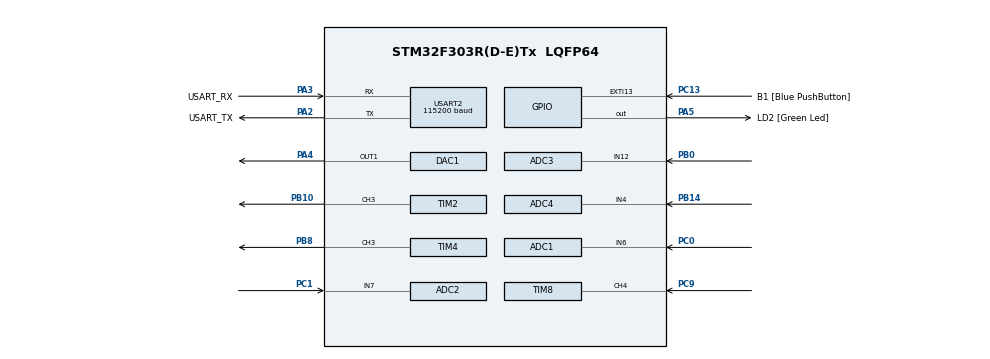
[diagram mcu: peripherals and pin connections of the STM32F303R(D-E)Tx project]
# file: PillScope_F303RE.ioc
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ADC1.AWD1HighThreshold=4095
ADC1.AWD1ITMode=ENABLE
ADC1.Channel-1\#ChannelRegularConversion=ADC_CHANNEL_VREFINT
ADC1.Channel-2\#ChannelRegularConversion=ADC_CHANNEL_6
ADC1.ClockPrescaler=ADC_CLOCK_SYNC_PCLK_DIV2
ADC1.DMAContinuousRequests=ENABLE
ADC1.EnableAnalogWatchDog1=true
ADC1.EnableInjectedConversion=DISABLE
ADC1.ExternalTrigConv=ADC_EXTERNALTRIGCONV_T3_TRGO
ADC1.NbrOfConversion=2
ADC1.NbrOfConversionFlag=1
ADC1.Offset-1\#ChannelRegularConversion=0
ADC1.Offset-2\#ChannelRegularConversion=0
ADC1.OffsetNumber-1\#ChannelRegularConversion=ADC_OFFSET_NONE
ADC1.OffsetNumber-2\#ChannelRegularConversion=ADC_OFFSET_NONE
ADC1.Rank-1\#ChannelRegularConversion=1
ADC1.Rank-2\#ChannelRegularConversion=2
ADC1.SamplingTime-1\#ChannelRegularConversion=ADC_SAMPLETIME_1CYCLE_5
ADC1.SamplingTime-2\#ChannelRegularConversion=ADC_SAMPLETIME_1CYCLE_5
ADC1.WatchdogChannel=ADC_CHANNEL_VREFINT
ADC1.master=1
ADC2.AWD1HighThreshold=4095
ADC2.AWD1ITMode=ENABLE
ADC2.Channel-1\#ChannelRegularConversion=ADC_CHANNEL_7
ADC2.ClockPrescaler=ADC_CLOCK_SYNC_PCLK_DIV2
ADC2.DMAContinuousRequests=ENABLE
ADC2.EnableAnalogWatchDog1=true
ADC2.ExternalTrigConv=ADC_EXTERNALTRIGCONV_T3_TRGO
ADC2.NbrOfConversion=1
ADC2.NbrOfConversionFlag=1
ADC2.Offset-1\#ChannelRegularConversion=0
ADC2.OffsetNumber-1\#ChannelRegularConversion=ADC_OFFSET_NONE
ADC2.Rank-1\#ChannelRegularConversion=1
ADC2.SamplingTime-1\#ChannelRegularConversion=ADC_SAMPLETIME_1CYCLE_5
ADC2.WatchdogChannel=ADC_CHANNEL_7
ADC3.AWD1HighThreshold=4095
ADC3.AWD1ITMode=ENABLE
ADC3.Channel-0\#ChannelRegularConversion=ADC_CHANNEL_12
ADC3.ClockPrescaler=ADC_CLOCK_SYNC_PCLK_DIV2
ADC3.DMAContinuousRequests=ENABLE
ADC3.EnableAnalogWatchDog1=true
ADC3.ExternalTrigConv=ADC_EXTERNALTRIGCONV_T3_TRGO
ADC3.NbrOfConversionFlag=1
ADC3.Offset-0\#ChannelRegularConversion=0
ADC3.OffsetNumber-0\#ChannelRegularConversion=ADC_OFFSET_NONE
ADC3.Rank-0\#ChannelRegularConversion=1
ADC3.SamplingTime-0\#ChannelRegularConversion=ADC_SAMPLETIME_1CYCLE_5
ADC3.WatchdogChannel=ADC_CHANNEL_12
ADC3.master=1
ADC4.AWD1HighThreshold=4095
ADC4.AWD1ITMode=ENABLE
ADC4.Channel-0\#ChannelRegularConversion=ADC_CHANNEL_4
ADC4.ClockPrescaler=ADC_CLOCK_SYNC_PCLK_DIV2
ADC4.DMAContinuousRequests=ENABLE
ADC4.EnableAnalogWatchDog1=true
ADC4.ExternalTrigConv=ADC_EXTERNALTRIGCONV_T3_TRGO
ADC4.NbrOfConversionFlag=1
ADC4.Offset-0\#ChannelRegularConversion=0
ADC4.OffsetNumber-0\#ChannelRegularConversion=ADC_OFFSET_NONE
ADC4.Rank-0\#ChannelRegularConversion=1
ADC4.SamplingTime-0\#ChannelRegularConversion=ADC_SAMPLETIME_1CYCLE_5
ADC4.SamplingTimeOPAMP-0\#ChannelRegularConversion=ADC_SAMPLETIME_61CYCLES_5
ADC4.WatchdogChannel=ADC_CHANNEL_4
DAC1.DAC_Trigger=DAC_TRIGGER_T6_TRGO
Dma.ADC1.0.Direction=DMA_PERIPH_TO_MEMORY
Dma.ADC1.0.Instance=DMA1_Channel1
Dma.ADC1.0.MemDataAlignment=DMA_MDATAALIGN_HALFWORD
Dma.ADC1.0.MemInc=DMA_MINC_ENABLE
Dma.ADC1.0.Mode=DMA_CIRCULAR
Dma.ADC1.0.PeriphDataAlignment=DMA_PDATAALIGN_HALFWORD
Dma.ADC1.0.PeriphInc=DMA_PINC_DISABLE
Dma.ADC1.0.Priority=DMA_PRIORITY_VERY_HIGH
Dma.ADC2.1.Direction=DMA_PERIPH_TO_MEMORY
Dma.ADC2.1.Instance=DMA2_Channel3
Dma.ADC2.1.MemDataAlignment=DMA_MDATAALIGN_HALFWORD
Dma.ADC2.1.MemInc=DMA_MINC_ENABLE
Dma.ADC2.1.Mode=DMA_CIRCULAR
Dma.ADC2.1.PeriphDataAlignment=DMA_PDATAALIGN_HALFWORD
Dma.ADC2.1.PeriphInc=DMA_PINC_DISABLE
Dma.ADC2.1.Priority=DMA_PRIORITY_VERY_HIGH
Dma.ADC3.2.Direction=DMA_PERIPH_TO_MEMORY
Dma.ADC3.2.Instance=DMA2_Channel5
Dma.ADC3.2.MemDataAlignment=DMA_MDATAALIGN_HALFWORD
Dma.ADC3.2.MemInc=DMA_MINC_ENABLE
Dma.ADC3.2.Mode=DMA_NORMAL
Dma.ADC3.2.PeriphDataAlignment=DMA_PDATAALIGN_HALFWORD
Dma.ADC3.2.PeriphInc=DMA_PINC_DISABLE
Dma.ADC3.2.Priority=DMA_PRIORITY_VERY_HIGH
Dma.ADC4.3.Direction=DMA_PERIPH_TO_MEMORY
Dma.ADC4.3.Instance=DMA2_Channel4
Dma.ADC4.3.MemDataAlignment=DMA_MDATAALIGN_HALFWORD
Dma.ADC4.3.MemInc=DMA_MINC_ENABLE
Dma.ADC4.3.Mode=DMA_CIRCULAR
Dma.ADC4.3.PeriphDataAlignment=DMA_PDATAALIGN_HALFWORD
Dma.ADC4.3.PeriphInc=DMA_PINC_DISABLE
Dma.ADC4.3.Priority=DMA_PRIORITY_VERY_HIGH
Dma.DAC1_CH1.5.Direction=DMA_MEMORY_TO_PERIPH
Dma.DAC1_CH1.5.Instance=DMA1_Channel3
Dma.DAC1_CH1.5.MemDataAlignment=DMA_MDATAALIGN_HALFWORD
Dma.DAC1_CH1.5.MemInc=DMA_MINC_ENABLE
Dma.DAC1_CH1.5.Mode=DMA_CIRCULAR
Dma.DAC1_CH1.5.PeriphDataAlignment=DMA_PDATAALIGN_HALFWORD
Dma.DAC1_CH1.5.PeriphInc=DMA_PINC_DISABLE
Dma.DAC1_CH1.5.Priority=DMA_PRIORITY_HIGH
Dma.Request0=ADC1
Dma.Request1=ADC2
Dma.Request2=ADC3
Dma.Request3=ADC4
Dma.Request4=TIM3_CH1/TRIG
Dma.Request5=DAC1_CH1
Dma.Request6=TIM8_CH4/TRIG/COM
Dma.TIM3_CH1/TRIG.4.Direction=DMA_PERIPH_TO_MEMORY
Dma.TIM3_CH1/TRIG.4.Instance=DMA1_Channel6
Dma.TIM3_CH1/TRIG.4.MemDataAlignment=DMA_MDATAALIGN_HALFWORD
Dma.TIM3_CH1/TRIG.4.MemInc=DMA_MINC_ENABLE
Dma.TIM3_CH1/TRIG.4.Mode=DMA_CIRCULAR
Dma.TIM3_CH1/TRIG.4.PeriphDataAlignment=DMA_PDATAALIGN_HALFWORD
Dma.TIM3_CH1/TRIG.4.PeriphInc=DMA_PINC_DISABLE
Dma.TIM3_CH1/TRIG.4.Priority=DMA_PRIORITY_VERY_HIGH
Dma.TIM8_CH4/TRIG/COM.6.Direction=DMA_PERIPH_TO_MEMORY
Dma.TIM8_CH4/TRIG/COM.6.Instance=DMA2_Channel2
Dma.TIM8_CH4/TRIG/COM.6.MemDataAlignment=DMA_MDATAALIGN_HALFWORD
Dma.TIM8_CH4/TRIG/COM.6.MemInc=DMA_MINC_ENABLE
Dma.TIM8_CH4/TRIG/COM.6.Mode=DMA_NORMAL
Dma.TIM8_CH4/TRIG/COM.6.PeriphDataAlignment=DMA_PDATAALIGN_HALFWORD
Dma.TIM8_CH4/TRIG/COM.6.PeriphInc=DMA_PINC_DISABLE
Dma.TIM8_CH4/TRIG/COM.6.Priority=DMA_PRIORITY_HIGH
Mcu.Family=STM32F3
Mcu.Name=STM32F303R(D-E)Tx
Mcu.Package=LQFP64
NVIC.PriorityGroup=NVIC_PRIORITYGROUP_4
PA13.GPIO_Label=TMS
PA13.Mode=Serial_Wire
PA13.Signal=SYS_JTMS-SWDIO
PA14.GPIO_Label=TCK
PA14.Mode=Serial_Wire
PA14.Signal=SYS_JTCK-SWCLK
PA2.GPIO_Label=USART_TX
PA2.GPIO_Mode=GPIO_MODE_AF_PP
PA2.GPIO_PuPd=GPIO_NOPULL
PA2.GPIO_Speed=GPIO_SPEED_FREQ_LOW
PA2.Mode=Asynchronous
PA2.Signal=USART2_TX
PA3.GPIO_Label=USART_RX
PA3.GPIO_Mode=GPIO_MODE_AF_PP
PA3.GPIO_PuPd=GPIO_NOPULL
PA3.GPIO_Speed=GPIO_SPEED_FREQ_LOW
PA3.Mode=Asynchronous
PA3.Signal=USART2_RX
PA4.Signal=COMP_DAC11_group
PA5.GPIO_Label=LD2 [Green Led]
PA5.GPIO_Mode=GPIO_MODE_OUTPUT_PP
PA5.GPIO_PuPd=GPIO_NOPULL
PA5.GPIO_Speed=GPIO_SPEED_FREQ_LOW
PA5.Signal=GPIO_Output
PB0.Mode=IN12-Single-Ended
PB0.Signal=ADC3_IN12
PB10.Signal=S_TIM2_CH3
PB14.Mode=IN4-Single-Ended
PB14.Signal=ADC4_IN4
PB3.GPIO_Label=SWO
PB3.Signal=SYS_JTDO-TRACESWO
PB8.Signal=S_TIM4_CH3
PC0.Signal=ADCx_IN6
PC1.Signal=ADCx_IN7
PC13.GPIO_Label=B1 [Blue PushButton]
PC13.GPIO_ModeDefaultEXTI=GPIO_MODE_IT_FALLING
PC13.Signal=GPXTI13
PC14-OSC32_IN.Mode=LSE-External-Oscillator
PC14-OSC32_IN.Signal=RCC_OSC32_IN
PC15-OSC32_OUT.Mode=LSE-External-Oscillator
PC15-OSC32_OUT.Signal=RCC_OSC32_OUT
PC9.Signal=S_TIM8_CH4
PF0-OSC_IN.Mode=HSE-External-Clock-Source
PF0-OSC_IN.Signal=RCC_OSC_IN
PF1-OSC_OUT.Signal=RCC_OSC_OUT
ProjectManager.HeapSize=0x200
ProjectManager.StackSize=0x400
ProjectManager.TargetToolchain=STM32CubeIDE
RCC.AHBFreq_Value=72000000
RCC.APB1CLKDivider=RCC_HCLK_DIV2
RCC.APB1Freq_Value=36000000
RCC.APB1TimFreq_Value=72000000
RCC.APB2Freq_Value=72000000
RCC.APB2TimFreq_Value=72000000
RCC.CortexFreq_Value=72000000
RCC.HCLKFreq_Value=72000000
RCC.HSE_VALUE=8000000
RCC.HSI_VALUE=8000000
RCC.PLLM=8
RCC.PLLMUL=RCC_PLL_MUL9
RCC.PLLN=336
RCC.PLLP=RCC_PLLP_DIV4
RCC.PLLQ=7
RCC.RCC_PLLsource_Clock_Source_FROM_HSE=RCC_HSE_PREDIV_DIV2
RCC.SYSCLKFreq_VALUE=72000000
RCC.SYSCLKSourceVirtual=RCC_SYSCLKSOURCE_PLLCLK
RCC.USBFreq_Value=72000000
SH.ADCx_IN6.0=ADC1_IN6,IN6-Single-Ended
SH.ADCx_IN7.0=ADC2_IN7,IN7-Single-Ended
SH.COMP_DAC11_group.0=DAC1_OUT1,DAC_OUT1
SH.S_TIM2_CH3.0=TIM2_CH3,PWM Generation3 CH3
SH.S_TIM4_CH3.0=TIM4_CH3,PWM Generation3 CH3
SH.S_TIM8_CH4.0=TIM8_CH4,Input_Capture4_from_TI4
TIM2.Channel-PWM\ Generation3\ CH3=TIM_CHANNEL_3
TIM2.Period=1000
TIM2.TIM_MasterOutputTrigger=TIM_TRGO_ENABLE
TIM2.TIM_MasterSlaveMode=TIM_MASTERSLAVEMODE_ENABLE
TIM3.AutoReloadPreload=TIM_AUTORELOAD_PRELOAD_ENABLE
TIM3.Channel-Output\ Compare1\ No\ Output=TIM_CHANNEL_1
TIM3.Period=72
TIM3.Prescaler=1000
TIM3.TIM_MasterOutputTrigger=TIM_TRGO_UPDATE
TIM4.AutoReloadPreload=TIM_AUTORELOAD_PRELOAD_ENABLE
TIM4.Channel-PWM\ Generation3\ CH3=TIM_CHANNEL_3
TIM4.Period=73
TIM4.Prescaler=1000
TIM4.TIM_MasterOutputTrigger=TIM_TRGO_UPDATE
TIM6.TIM_MasterOutputTrigger=TIM_TRGO_UPDATE
TIM8.AutoReloadPreload=TIM_AUTORELOAD_PRELOAD_DISABLE
TIM8.Channel-Input_Capture4_from_TI4=TIM_CHANNEL_4
USART2.BaudRate=115200
USART2.VirtualMode-Asynchronous=VM_ASYNC
VP_ADC1_Vref_Input.Mode=IN-Vrefint
VP_TIM2_VS_ClockSourceINT.Mode=Internal
VP_TIM3_VS_ClockSourceINT.Mode=Internal
VP_TIM3_VS_no_output1.Mode=Output Compare1 No Output
VP_TIM4_VS_ClockSourceINT.Mode=Internal
VP_TIM4_VS_ClockSourceITR.Mode=TriggerSource_ITR1
VP_TIM4_VS_ControllerModeTrigger.Mode=Trigger Mode
VP_TIM6_VS_ClockSourceINT.Mode=Enable_Timer
board=NUCLEO-F303RE

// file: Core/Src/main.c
/* USER CODE BEGIN Header */
/**
  ******************************************************************************
  * @file           : main.c
  * @brief          : Main program body
  ******************************************************************************
  * @attention
  *
  * <h2><center>&copy; Copyright (c) 2021 STMicroelectronics.
  * All rights reserved.</center></h2>
  *
  * This software component is licensed by ST under BSD 3-Clause license,
  * the "License"; You may not use this file except in compliance with the
  * License. You may obtain a copy of the License at:
  *                        opensource.org/licenses/BSD-3-Clause
  *
  ******************************************************************************
  */
/* USER CODE END Header */
#include "main.h"

/* USER CODE BEGIN Includes */
#include "app.h"
/* USER CODE END Includes */

TIM_HandleTypeDef htim6;

void SystemClock_Config(void);
static void MX_GPIO_Init(void);
static void MX_DMA_Init(void);
static void MX_USART2_UART_Init(void);
static void MX_ADC1_Init(void);
static void MX_ADC2_Init(void);
static void MX_ADC3_Init(void);
static void MX_ADC4_Init(void);
static void MX_TIM3_Init(void);
static void MX_TIM2_Init(void);
static void MX_TIM4_Init(void);
static void MX_DAC1_Init(void);
static void MX_TIM8_Init(void);
static void MX_TIM6_Init(void);

int main(void)
{

  /* MCU Configuration--------------------------------------------------------*/

  /* Reset of all peripherals, Initializes the Flash interface and the Systick. */
  HAL_Init();

  /* Configure the system clock */
  SystemClock_Config();

  /* Initialize all configured peripherals */
  MX_GPIO_Init();
  MX_DMA_Init();
  MX_USART2_UART_Init();
  MX_ADC1_Init();
  MX_ADC2_Init();
  MX_ADC3_Init();
  MX_ADC4_Init();
  MX_TIM3_Init();
  MX_TIM2_Init();
  MX_TIM4_Init();
  MX_DAC1_Init();
  MX_TIM8_Init();
  MX_TIM6_Init();

  /* Infinite loop */
  /* USER CODE BEGIN WHILE */
  app_main();
    /* USER CODE END WHILE */

}

void SystemClock_Config(void)
{
  LL_FLASH_SetLatency(LL_FLASH_LATENCY_2);
  while(LL_FLASH_GetLatency()!= LL_FLASH_LATENCY_2)
  {
  }
  LL_RCC_HSI_Enable();

   /* Wait till HSI is ready */
  while(LL_RCC_HSI_IsReady() != 1)
  {

  }
  LL_RCC_HSI_SetCalibTrimming(16);
  LL_RCC_PLL_ConfigDomain_SYS(LL_RCC_PLLSOURCE_HSI, LL_RCC_PLL_MUL_9, LL_RCC_PREDIV_DIV_1);
  LL_RCC_PLL_Enable();

   /* Wait till PLL is ready */
  while(LL_RCC_PLL_IsReady() != 1)
  {

  }
  LL_RCC_SetAHBPrescaler(LL_RCC_SYSCLK_DIV_1);
  LL_RCC_SetAPB1Prescaler(LL_RCC_APB1_DIV_2);
  LL_RCC_SetAPB2Prescaler(LL_RCC_APB1_DIV_1);
  LL_RCC_SetSysClkSource(LL_RCC_SYS_CLKSOURCE_PLL);

   /* Wait till System clock is ready */
  while(LL_RCC_GetSysClkSource() != LL_RCC_SYS_CLKSOURCE_STATUS_PLL)
  {

  }
  LL_SetSystemCoreClock(72000000);

   /* Update the time base */
  if (HAL_InitTick (TICK_INT_PRIORITY) != HAL_OK)
  {
    Error_Handler();
  }
  LL_RCC_SetUSARTClockSource(LL_RCC_USART2_CLKSOURCE_PCLK1);
  LL_RCC_SetTIMClockSource(LL_RCC_TIM8_CLKSOURCE_PCLK2);
  LL_RCC_SetTIMClockSource(LL_RCC_TIM2_CLKSOURCE_PCLK1);
  LL_RCC_SetTIMClockSource(LL_RCC_TIM34_CLKSOURCE_PCLK1);
}

static void MX_ADC1_Init(void)
{

  LL_ADC_InitTypeDef ADC_InitStruct = {0};
  LL_ADC_REG_InitTypeDef ADC_REG_InitStruct = {0};
  LL_ADC_CommonInitTypeDef ADC_CommonInitStruct = {0};

  LL_GPIO_InitTypeDef GPIO_InitStruct = {0};

  /* Peripheral clock enable */
  LL_AHB1_GRP1_EnableClock(LL_AHB1_GRP1_PERIPH_ADC12);

  LL_AHB1_GRP1_EnableClock(LL_AHB1_GRP1_PERIPH_GPIOC);
  /**ADC1 GPIO Configuration
  PC0   ------> ADC1_IN6
  */
  GPIO_InitStruct.Pin = LL_GPIO_PIN_0;
  GPIO_InitStruct.Mode = LL_GPIO_MODE_ANALOG;
  GPIO_InitStruct.Pull = LL_GPIO_PULL_NO;
  LL_GPIO_Init(GPIOC, &GPIO_InitStruct);

  /* ADC1 DMA Init */

  /* ADC1 Init */
  LL_DMA_SetDataTransferDirection(DMA1, LL_DMA_CHANNEL_1, LL_DMA_DIRECTION_PERIPH_TO_MEMORY);

  LL_DMA_SetChannelPriorityLevel(DMA1, LL_DMA_CHANNEL_1, LL_DMA_PRIORITY_VERYHIGH);

  LL_DMA_SetMode(DMA1, LL_DMA_CHANNEL_1, LL_DMA_MODE_CIRCULAR);

  LL_DMA_SetPeriphIncMode(DMA1, LL_DMA_CHANNEL_1, LL_DMA_PERIPH_NOINCREMENT);

  LL_DMA_SetMemoryIncMode(DMA1, LL_DMA_CHANNEL_1, LL_DMA_MEMORY_INCREMENT);

  LL_DMA_SetPeriphSize(DMA1, LL_DMA_CHANNEL_1, LL_DMA_PDATAALIGN_HALFWORD);

  LL_DMA_SetMemorySize(DMA1, LL_DMA_CHANNEL_1, LL_DMA_MDATAALIGN_HALFWORD);

  /** Common config
  */
  ADC_InitStruct.Resolution = LL_ADC_RESOLUTION_12B;
  ADC_InitStruct.DataAlignment = LL_ADC_DATA_ALIGN_RIGHT;
  ADC_InitStruct.LowPowerMode = LL_ADC_LP_MODE_NONE;
  LL_ADC_Init(ADC1, &ADC_InitStruct);
  ADC_REG_InitStruct.TriggerSource = LL_ADC_REG_TRIG_EXT_TIM3_TRGO_ADC12;
  ADC_REG_InitStruct.SequencerLength = LL_ADC_REG_SEQ_SCAN_ENABLE_2RANKS;
  ADC_REG_InitStruct.SequencerDiscont = LL_ADC_REG_SEQ_DISCONT_DISABLE;
  ADC_REG_InitStruct.ContinuousMode = LL_ADC_REG_CONV_SINGLE;
  ADC_REG_InitStruct.DMATransfer = LL_ADC_REG_DMA_TRANSFER_UNLIMITED;
  ADC_REG_InitStruct.Overrun = LL_ADC_REG_OVR_DATA_OVERWRITTEN;
  LL_ADC_REG_Init(ADC1, &ADC_REG_InitStruct);

   /* Enable ADC internal voltage regulator */
   LL_ADC_EnableInternalRegulator(ADC1);
   /* Delay for ADC internal voltage regulator stabilization. */
   /* Compute number of CPU cycles to wait for, from delay in us. */
   /* Note: Variable divided by 2 to compensate partially */
   /* CPU processing cycles (depends on compilation optimization). */
   /* Note: If system core clock frequency is below 200kHz, wait time */
   /* is only a few CPU processing cycles. */
   uint32_t wait_loop_index;
   wait_loop_index = ((LL_ADC_DELAY_INTERNAL_REGUL_STAB_US * (SystemCoreClock / (100000 * 2))) / 10);
   while(wait_loop_index != 0)
     {
   wait_loop_index--;
     }
  ADC_CommonInitStruct.CommonClock = LL_ADC_CLOCK_SYNC_PCLK_DIV2;
  ADC_CommonInitStruct.Multimode = LL_ADC_MULTI_INDEPENDENT;
  LL_ADC_CommonInit(__LL_ADC_COMMON_INSTANCE(ADC1), &ADC_CommonInitStruct);
  LL_ADC_REG_SetTriggerEdge(ADC1, LL_ADC_REG_TRIG_EXT_RISING);
  /** Configure Analog WatchDog 1
  */
  LL_ADC_SetAnalogWDMonitChannels(ADC1, LL_ADC_AWD1, LL_ADC_AWD_CH_VREFINT_REG);
  LL_ADC_ConfigAnalogWDThresholds(ADC1, LL_ADC_AWD1, 4095, 0);
  LL_ADC_EnableIT_AWD1(ADC1);
  /** Configure Regular Channel
  */
  LL_ADC_REG_SetSequencerRanks(ADC1, LL_ADC_REG_RANK_1, LL_ADC_CHANNEL_VREFINT);
  LL_ADC_SetChannelSamplingTime(ADC1, LL_ADC_CHANNEL_VREFINT, LL_ADC_SAMPLINGTIME_1CYCLE_5);
  LL_ADC_SetChannelSingleDiff(ADC1, LL_ADC_CHANNEL_VREFINT, LL_ADC_SINGLE_ENDED);
  LL_ADC_SetCommonPathInternalCh(__LL_ADC_COMMON_INSTANCE(ADC1), LL_ADC_PATH_INTERNAL_VREFINT);
  /** Configure Regular Channel
  */
  LL_ADC_REG_SetSequencerRanks(ADC1, LL_ADC_REG_RANK_2, LL_ADC_CHANNEL_6);
  LL_ADC_SetChannelSamplingTime(ADC1, LL_ADC_CHANNEL_6, LL_ADC_SAMPLINGTIME_1CYCLE_5);
  LL_ADC_SetChannelSingleDiff(ADC1, LL_ADC_CHANNEL_6, LL_ADC_SINGLE_ENDED);

}

static void MX_ADC2_Init(void)
{

  LL_ADC_InitTypeDef ADC_InitStruct = {0};
  LL_ADC_REG_InitTypeDef ADC_REG_InitStruct = {0};

  LL_GPIO_InitTypeDef GPIO_InitStruct = {0};

  /* Peripheral clock enable */
  LL_AHB1_GRP1_EnableClock(LL_AHB1_GRP1_PERIPH_ADC12);

  LL_AHB1_GRP1_EnableClock(LL_AHB1_GRP1_PERIPH_GPIOC);
  /**ADC2 GPIO Configuration
  PC1   ------> ADC2_IN7
  */
  GPIO_InitStruct.Pin = LL_GPIO_PIN_1;
  GPIO_InitStruct.Mode = LL_GPIO_MODE_ANALOG;
  GPIO_InitStruct.Pull = LL_GPIO_PULL_NO;
  LL_GPIO_Init(GPIOC, &GPIO_InitStruct);

  /* ADC2 DMA Init */

  /* ADC2 Init */
  LL_DMA_SetDataTransferDirection(DMA2, LL_DMA_CHANNEL_3, LL_DMA_DIRECTION_PERIPH_TO_MEMORY);

  LL_DMA_SetChannelPriorityLevel(DMA2, LL_DMA_CHANNEL_3, LL_DMA_PRIORITY_VERYHIGH);

  LL_DMA_SetMode(DMA2, LL_DMA_CHANNEL_3, LL_DMA_MODE_CIRCULAR);

  LL_DMA_SetPeriphIncMode(DMA2, LL_DMA_CHANNEL_3, LL_DMA_PERIPH_NOINCREMENT);

  LL_DMA_SetMemoryIncMode(DMA2, LL_DMA_CHANNEL_3, LL_DMA_MEMORY_INCREMENT);

  LL_DMA_SetPeriphSize(DMA2, LL_DMA_CHANNEL_3, LL_DMA_PDATAALIGN_HALFWORD);

  LL_DMA_SetMemorySize(DMA2, LL_DMA_CHANNEL_3, LL_DMA_MDATAALIGN_HALFWORD);

  LL_SYSCFG_SetRemapDMA_ADC(LL_SYSCFG_ADC24_RMP_DMA2_CH34);

  /** Common config
  */
  ADC_InitStruct.Resolution = LL_ADC_RESOLUTION_12B;
  ADC_InitStruct.DataAlignment = LL_ADC_DATA_ALIGN_RIGHT;
  ADC_InitStruct.LowPowerMode = LL_ADC_LP_MODE_NONE;
  LL_ADC_Init(ADC2, &ADC_InitStruct);
  ADC_REG_InitStruct.TriggerSource = LL_ADC_REG_TRIG_EXT_TIM3_TRGO_ADC12;
  ADC_REG_InitStruct.SequencerLength = LL_ADC_REG_SEQ_SCAN_DISABLE;
  ADC_REG_InitStruct.SequencerDiscont = LL_ADC_REG_SEQ_DISCONT_DISABLE;
  ADC_REG_InitStruct.ContinuousMode = LL_ADC_REG_CONV_SINGLE;
  ADC_REG_InitStruct.DMATransfer = LL_ADC_REG_DMA_TRANSFER_UNLIMITED;
  ADC_REG_InitStruct.Overrun = LL_ADC_REG_OVR_DATA_OVERWRITTEN;
  LL_ADC_REG_Init(ADC2, &ADC_REG_InitStruct);

   /* Enable ADC internal voltage regulator */
   LL_ADC_EnableInternalRegulator(ADC1);
   /* Delay for ADC internal voltage regulator stabilization. */
   /* Compute number of CPU cycles to wait for, from delay in us. */
   /* Note: Variable divided by 2 to compensate partially */
   /* CPU processing cycles (depends on compilation optimization). */
   /* Note: If system core clock frequency is below 200kHz, wait time */
   /* is only a few CPU processing cycles. */
   uint32_t wait_loop_index;
   wait_loop_index = ((LL_ADC_DELAY_INTERNAL_REGUL_STAB_US * (SystemCoreClock / (100000 * 2))) / 10);
   while(wait_loop_index != 0)
     {
   wait_loop_index--;
     }
  LL_ADC_REG_SetTriggerEdge(ADC2, LL_ADC_REG_TRIG_EXT_RISING);
  /** Configure Analog WatchDog 1
  */
  LL_ADC_SetAnalogWDMonitChannels(ADC2, LL_ADC_AWD1, LL_ADC_AWD_CHANNEL_7_REG);
  LL_ADC_ConfigAnalogWDThresholds(ADC2, LL_ADC_AWD1, 4095, 0);
  LL_ADC_EnableIT_AWD1(ADC2);
  /** Configure Regular Channel
  */
  LL_ADC_REG_SetSequencerRanks(ADC2, LL_ADC_REG_RANK_1, LL_ADC_CHANNEL_7);
  LL_ADC_SetChannelSamplingTime(ADC2, LL_ADC_CHANNEL_7, LL_ADC_SAMPLINGTIME_1CYCLE_5);
  LL_ADC_SetChannelSingleDiff(ADC2, LL_ADC_CHANNEL_7, LL_ADC_SINGLE_ENDED);

}

static void MX_ADC3_Init(void)
{

  LL_ADC_InitTypeDef ADC_InitStruct = {0};
  LL_ADC_REG_InitTypeDef ADC_REG_InitStruct = {0};
  LL_ADC_CommonInitTypeDef ADC_CommonInitStruct = {0};

  LL_GPIO_InitTypeDef GPIO_InitStruct = {0};

  /* Peripheral clock enable */
  LL_AHB1_GRP1_EnableClock(LL_AHB1_GRP1_PERIPH_ADC34);

  LL_AHB1_GRP1_EnableClock(LL_AHB1_GRP1_PERIPH_GPIOB);
  /**ADC3 GPIO Configuration
  PB0   ------> ADC3_IN12
  */
  GPIO_InitStruct.Pin = LL_GPIO_PIN_0;
  GPIO_InitStruct.Mode = LL_GPIO_MODE_ANALOG;
  GPIO_InitStruct.Pull = LL_GPIO_PULL_NO;
  LL_GPIO_Init(GPIOB, &GPIO_InitStruct);

  /* ADC3 DMA Init */

  /* ADC3 Init */
  LL_DMA_SetDataTransferDirection(DMA2, LL_DMA_CHANNEL_5, LL_DMA_DIRECTION_PERIPH_TO_MEMORY);

  LL_DMA_SetChannelPriorityLevel(DMA2, LL_DMA_CHANNEL_5, LL_DMA_PRIORITY_VERYHIGH);

  LL_DMA_SetMode(DMA2, LL_DMA_CHANNEL_5, LL_DMA_MODE_NORMAL);

  LL_DMA_SetPeriphIncMode(DMA2, LL_DMA_CHANNEL_5, LL_DMA_PERIPH_NOINCREMENT);

  LL_DMA_SetMemoryIncMode(DMA2, LL_DMA_CHANNEL_5, LL_DMA_MEMORY_INCREMENT);

  LL_DMA_SetPeriphSize(DMA2, LL_DMA_CHANNEL_5, LL_DMA_PDATAALIGN_HALFWORD);

  LL_DMA_SetMemorySize(DMA2, LL_DMA_CHANNEL_5, LL_DMA_MDATAALIGN_HALFWORD);

  /** Common config
  */
  ADC_InitStruct.Resolution = LL_ADC_RESOLUTION_12B;
  ADC_InitStruct.DataAlignment = LL_ADC_DATA_ALIGN_RIGHT;
  ADC_InitStruct.LowPowerMode = LL_ADC_LP_MODE_NONE;
  LL_ADC_Init(ADC3, &ADC_InitStruct);
  ADC_REG_InitStruct.TriggerSource = LL_ADC_REG_TRIG_EXT_TIM3_TRGO__ADC34;
  ADC_REG_InitStruct.SequencerLength = LL_ADC_REG_SEQ_SCAN_DISABLE;
  ADC_REG_InitStruct.SequencerDiscont = LL_ADC_REG_SEQ_DISCONT_DISABLE;
  ADC_REG_InitStruct.ContinuousMode = LL_ADC_REG_CONV_SINGLE;
  ADC_REG_InitStruct.DMATransfer = LL_ADC_REG_DMA_TRANSFER_UNLIMITED;
  ADC_REG_InitStruct.Overrun = LL_ADC_REG_OVR_DATA_OVERWRITTEN;
  LL_ADC_REG_Init(ADC3, &ADC_REG_InitStruct);

   /* Enable ADC internal voltage regulator */
   LL_ADC_EnableInternalRegulator(ADC1);
   /* Delay for ADC internal voltage regulator stabilization. */
   /* Compute number of CPU cycles to wait for, from delay in us. */
   /* Note: Variable divided by 2 to compensate partially */
   /* CPU processing cycles (depends on compilation optimization). */
   /* Note: If system core clock frequency is below 200kHz, wait time */
   /* is only a few CPU processing cycles. */
   uint32_t wait_loop_index;
   wait_loop_index = ((LL_ADC_DELAY_INTERNAL_REGUL_STAB_US * (SystemCoreClock / (100000 * 2))) / 10);
   while(wait_loop_index != 0)
     {
   wait_loop_index--;
     }
  ADC_CommonInitStruct.CommonClock = LL_ADC_CLOCK_SYNC_PCLK_DIV2;
  ADC_CommonInitStruct.Multimode = LL_ADC_MULTI_INDEPENDENT;
  LL_ADC_CommonInit(__LL_ADC_COMMON_INSTANCE(ADC3), &ADC_CommonInitStruct);
  LL_ADC_REG_SetTriggerEdge(ADC3, LL_ADC_REG_TRIG_EXT_RISING);
  /** Configure Analog WatchDog 1
  */
  LL_ADC_SetAnalogWDMonitChannels(ADC3, LL_ADC_AWD1, LL_ADC_AWD_CHANNEL_12_REG);
  LL_ADC_ConfigAnalogWDThresholds(ADC3, LL_ADC_AWD1, 4095, 0);
  LL_ADC_EnableIT_AWD1(ADC3);
  /** Configure Regular Channel
  */
  LL_ADC_REG_SetSequencerRanks(ADC3, LL_ADC_REG_RANK_1, LL_ADC_CHANNEL_12);
  LL_ADC_SetChannelSamplingTime(ADC3, LL_ADC_CHANNEL_12, LL_ADC_SAMPLINGTIME_1CYCLE_5);
  LL_ADC_SetChannelSingleDiff(ADC3, LL_ADC_CHANNEL_12, LL_ADC_SINGLE_ENDED);

}

static void MX_ADC4_Init(void)
{

  LL_ADC_InitTypeDef ADC_InitStruct = {0};
  LL_ADC_REG_InitTypeDef ADC_REG_InitStruct = {0};

  LL_GPIO_InitTypeDef GPIO_InitStruct = {0};

  /* Peripheral clock enable */
  LL_AHB1_GRP1_EnableClock(LL_AHB1_GRP1_PERIPH_ADC34);

  LL_AHB1_GRP1_EnableClock(LL_AHB1_GRP1_PERIPH_GPIOB);
  /**ADC4 GPIO Configuration
  PB14   ------> ADC4_IN4
  */
  GPIO_InitStruct.Pin = LL_GPIO_PIN_14;
  GPIO_InitStruct.Mode = LL_GPIO_MODE_ANALOG;
  GPIO_InitStruct.Pull = LL_GPIO_PULL_NO;
  LL_GPIO_Init(GPIOB, &GPIO_InitStruct);

  /* ADC4 DMA Init */

  /* ADC4 Init */
  LL_DMA_SetDataTransferDirection(DMA2, LL_DMA_CHANNEL_4, LL_DMA_DIRECTION_PERIPH_TO_MEMORY);

  LL_DMA_SetChannelPriorityLevel(DMA2, LL_DMA_CHANNEL_4, LL_DMA_PRIORITY_VERYHIGH);

  LL_DMA_SetMode(DMA2, LL_DMA_CHANNEL_4, LL_DMA_MODE_CIRCULAR);

  LL_DMA_SetPeriphIncMode(DMA2, LL_DMA_CHANNEL_4, LL_DMA_PERIPH_NOINCREMENT);

  LL_DMA_SetMemoryIncMode(DMA2, LL_DMA_CHANNEL_4, LL_DMA_MEMORY_INCREMENT);

  LL_DMA_SetPeriphSize(DMA2, LL_DMA_CHANNEL_4, LL_DMA_PDATAALIGN_HALFWORD);

  LL_DMA_SetMemorySize(DMA2, LL_DMA_CHANNEL_4, LL_DMA_MDATAALIGN_HALFWORD);

  LL_SYSCFG_SetRemapDMA_ADC(LL_SYSCFG_ADC24_RMP_DMA2_CH34);

  /** Common config
  */
  ADC_InitStruct.Resolution = LL_ADC_RESOLUTION_12B;
  ADC_InitStruct.DataAlignment = LL_ADC_DATA_ALIGN_RIGHT;
  ADC_InitStruct.LowPowerMode = LL_ADC_LP_MODE_NONE;
  LL_ADC_Init(ADC4, &ADC_InitStruct);
  ADC_REG_InitStruct.TriggerSource = LL_ADC_REG_TRIG_EXT_TIM3_TRGO__ADC34;
  ADC_REG_InitStruct.SequencerLength = LL_ADC_REG_SEQ_SCAN_DISABLE;
  ADC_REG_InitStruct.SequencerDiscont = LL_ADC_REG_SEQ_DISCONT_DISABLE;
  ADC_REG_InitStruct.ContinuousMode = LL_ADC_REG_CONV_SINGLE;
  ADC_REG_InitStruct.DMATransfer = LL_ADC_REG_DMA_TRANSFER_UNLIMITED;
  ADC_REG_InitStruct.Overrun = LL_ADC_REG_OVR_DATA_OVERWRITTEN;
  LL_ADC_REG_Init(ADC4, &ADC_REG_InitStruct);

   /* Enable ADC internal voltage regulator */
   LL_ADC_EnableInternalRegulator(ADC1);
   /* Delay for ADC internal voltage regulator stabilization. */
   /* Compute number of CPU cycles to wait for, from delay in us. */
   /* Note: Variable divided by 2 to compensate partially */
   /* CPU processing cycles (depends on compilation optimization). */
   /* Note: If system core clock frequency is below 200kHz, wait time */
   /* is only a few CPU processing cycles. */
   uint32_t wait_loop_index;
   wait_loop_index = ((LL_ADC_DELAY_INTERNAL_REGUL_STAB_US * (SystemCoreClock / (100000 * 2))) / 10);
   while(wait_loop_index != 0)
     {
   wait_loop_index--;
     }
  LL_ADC_REG_SetTriggerEdge(ADC4, LL_ADC_REG_TRIG_EXT_RISING);
  /** Configure Analog WatchDog 1
  */
  LL_ADC_SetAnalogWDMonitChannels(ADC4, LL_ADC_AWD1, LL_ADC_AWD_CHANNEL_4_REG);
  LL_ADC_ConfigAnalogWDThresholds(ADC4, LL_ADC_AWD1, 4095, 0);
  LL_ADC_EnableIT_AWD1(ADC4);
  /** Configure Regular Channel
  */
  LL_ADC_REG_SetSequencerRanks(ADC4, LL_ADC_REG_RANK_1, LL_ADC_CHANNEL_4);
  LL_ADC_SetChannelSamplingTime(ADC4, LL_ADC_CHANNEL_4, LL_ADC_SAMPLINGTIME_1CYCLE_5);
  LL_ADC_SetChannelSingleDiff(ADC4, LL_ADC_CHANNEL_4, LL_ADC_SINGLE_ENDED);

}

static void MX_DAC1_Init(void)
{

  LL_DAC_InitTypeDef DAC_InitStruct = {0};

  LL_GPIO_InitTypeDef GPIO_InitStruct = {0};

  /* Peripheral clock enable */
  LL_APB1_GRP1_EnableClock(LL_APB1_GRP1_PERIPH_DAC1);

  LL_AHB1_GRP1_EnableClock(LL_AHB1_GRP1_PERIPH_GPIOA);
  /**DAC1 GPIO Configuration
  PA4   ------> DAC1_OUT1
  */
  GPIO_InitStruct.Pin = LL_GPIO_PIN_4;
  GPIO_InitStruct.Mode = LL_GPIO_MODE_ANALOG;
  GPIO_InitStruct.Pull = LL_GPIO_PULL_NO;
  LL_GPIO_Init(GPIOA, &GPIO_InitStruct);

  /* DAC1 DMA Init */

  /* DAC1_CH1 Init */
  LL_DMA_SetDataTransferDirection(DMA1, LL_DMA_CHANNEL_3, LL_DMA_DIRECTION_MEMORY_TO_PERIPH);

  LL_DMA_SetChannelPriorityLevel(DMA1, LL_DMA_CHANNEL_3, LL_DMA_PRIORITY_HIGH);

  LL_DMA_SetMode(DMA1, LL_DMA_CHANNEL_3, LL_DMA_MODE_CIRCULAR);

  LL_DMA_SetPeriphIncMode(DMA1, LL_DMA_CHANNEL_3, LL_DMA_PERIPH_NOINCREMENT);

  LL_DMA_SetMemoryIncMode(DMA1, LL_DMA_CHANNEL_3, LL_DMA_MEMORY_INCREMENT);

  LL_DMA_SetPeriphSize(DMA1, LL_DMA_CHANNEL_3, LL_DMA_PDATAALIGN_HALFWORD);

  LL_DMA_SetMemorySize(DMA1, LL_DMA_CHANNEL_3, LL_DMA_MDATAALIGN_HALFWORD);

  LL_SYSCFG_SetRemapDMA_DAC(LL_SYSCFG_DAC1_CH1_RMP_DMA1_CH3);

  /** DAC channel OUT1 config
  */
  DAC_InitStruct.TriggerSource = LL_DAC_TRIG_EXT_TIM6_TRGO;
  DAC_InitStruct.WaveAutoGeneration = LL_DAC_WAVE_AUTO_GENERATION_NONE;
  DAC_InitStruct.OutputBuffer = LL_DAC_OUTPUT_BUFFER_ENABLE;
  LL_DAC_Init(DAC1, LL_DAC_CHANNEL_1, &DAC_InitStruct);
  LL_DAC_EnableTrigger(DAC1, LL_DAC_CHANNEL_1);

}

static void MX_TIM2_Init(void)
{

  LL_TIM_InitTypeDef TIM_InitStruct = {0};
  LL_TIM_OC_InitTypeDef TIM_OC_InitStruct = {0};

  LL_GPIO_InitTypeDef GPIO_InitStruct = {0};

  /* Peripheral clock enable */
  LL_APB1_GRP1_EnableClock(LL_APB1_GRP1_PERIPH_TIM2);

  TIM_InitStruct.Prescaler = 0;
  TIM_InitStruct.CounterMode = LL_TIM_COUNTERMODE_UP;
  TIM_InitStruct.Autoreload = 1000;
  TIM_InitStruct.ClockDivision = LL_TIM_CLOCKDIVISION_DIV1;
  LL_TIM_Init(TIM2, &TIM_InitStruct);
  LL_TIM_DisableARRPreload(TIM2);
  LL_TIM_SetClockSource(TIM2, LL_TIM_CLOCKSOURCE_INTERNAL);
  LL_TIM_OC_EnablePreload(TIM2, LL_TIM_CHANNEL_CH3);
  TIM_OC_InitStruct.OCMode = LL_TIM_OCMODE_PWM1;
  TIM_OC_InitStruct.OCState = LL_TIM_OCSTATE_DISABLE;
  TIM_OC_InitStruct.OCNState = LL_TIM_OCSTATE_DISABLE;
  TIM_OC_InitStruct.CompareValue = 0;
  TIM_OC_InitStruct.OCPolarity = LL_TIM_OCPOLARITY_HIGH;
  LL_TIM_OC_Init(TIM2, LL_TIM_CHANNEL_CH3, &TIM_OC_InitStruct);
  LL_TIM_OC_DisableFast(TIM2, LL_TIM_CHANNEL_CH3);
  LL_TIM_SetTriggerOutput(TIM2, LL_TIM_TRGO_ENABLE);
  LL_TIM_EnableMasterSlaveMode(TIM2);
  LL_AHB1_GRP1_EnableClock(LL_AHB1_GRP1_PERIPH_GPIOB);
  /**TIM2 GPIO Configuration
  PB10   ------> TIM2_CH3
  */
  GPIO_InitStruct.Pin = LL_GPIO_PIN_10;
  GPIO_InitStruct.Mode = LL_GPIO_MODE_ALTERNATE;
  GPIO_InitStruct.Speed = LL_GPIO_SPEED_FREQ_LOW;
  GPIO_InitStruct.OutputType = LL_GPIO_OUTPUT_PUSHPULL;
  GPIO_InitStruct.Pull = LL_GPIO_PULL_NO;
  GPIO_InitStruct.Alternate = LL_GPIO_AF_1;
  LL_GPIO_Init(GPIOB, &GPIO_InitStruct);

}

static void MX_TIM3_Init(void)
{

  LL_TIM_InitTypeDef TIM_InitStruct = {0};
  LL_TIM_OC_InitTypeDef TIM_OC_InitStruct = {0};

  /* Peripheral clock enable */
  LL_APB1_GRP1_EnableClock(LL_APB1_GRP1_PERIPH_TIM3);

  /* TIM3 DMA Init */

  /* TIM3_CH1_TRIG Init */
  LL_DMA_SetDataTransferDirection(DMA1, LL_DMA_CHANNEL_6, LL_DMA_DIRECTION_PERIPH_TO_MEMORY);

  LL_DMA_SetChannelPriorityLevel(DMA1, LL_DMA_CHANNEL_6, LL_DMA_PRIORITY_VERYHIGH);

  LL_DMA_SetMode(DMA1, LL_DMA_CHANNEL_6, LL_DMA_MODE_CIRCULAR);

  LL_DMA_SetPeriphIncMode(DMA1, LL_DMA_CHANNEL_6, LL_DMA_PERIPH_NOINCREMENT);

  LL_DMA_SetMemoryIncMode(DMA1, LL_DMA_CHANNEL_6, LL_DMA_MEMORY_INCREMENT);

  LL_DMA_SetPeriphSize(DMA1, LL_DMA_CHANNEL_6, LL_DMA_PDATAALIGN_HALFWORD);

  LL_DMA_SetMemorySize(DMA1, LL_DMA_CHANNEL_6, LL_DMA_MDATAALIGN_HALFWORD);

  TIM_InitStruct.Prescaler = 1000;
  TIM_InitStruct.CounterMode = LL_TIM_COUNTERMODE_UP;
  TIM_InitStruct.Autoreload = 72;
  TIM_InitStruct.ClockDivision = LL_TIM_CLOCKDIVISION_DIV1;
  LL_TIM_Init(TIM3, &TIM_InitStruct);
  LL_TIM_EnableARRPreload(TIM3);
  LL_TIM_SetClockSource(TIM3, LL_TIM_CLOCKSOURCE_INTERNAL);
  TIM_OC_InitStruct.OCMode = LL_TIM_OCMODE_FROZEN;
  TIM_OC_InitStruct.OCState = LL_TIM_OCSTATE_DISABLE;
  TIM_OC_InitStruct.OCNState = LL_TIM_OCSTATE_DISABLE;
  TIM_OC_InitStruct.CompareValue = 0;
  TIM_OC_InitStruct.OCPolarity = LL_TIM_OCPOLARITY_HIGH;
  LL_TIM_OC_Init(TIM3, LL_TIM_CHANNEL_CH1, &TIM_OC_InitStruct);
  LL_TIM_OC_DisableFast(TIM3, LL_TIM_CHANNEL_CH1);
  LL_TIM_SetTriggerOutput(TIM3, LL_TIM_TRGO_UPDATE);
  LL_TIM_DisableMasterSlaveMode(TIM3);

}

static void MX_TIM4_Init(void)
{

  LL_TIM_InitTypeDef TIM_InitStruct = {0};
  LL_TIM_OC_InitTypeDef TIM_OC_InitStruct = {0};

  LL_GPIO_InitTypeDef GPIO_InitStruct = {0};

  /* Peripheral clock enable */
  LL_APB1_GRP1_EnableClock(LL_APB1_GRP1_PERIPH_TIM4);

  TIM_InitStruct.Prescaler = 1000;
  TIM_InitStruct.CounterMode = LL_TIM_COUNTERMODE_UP;
  TIM_InitStruct.Autoreload = 73;
  TIM_InitStruct.ClockDivision = LL_TIM_CLOCKDIVISION_DIV1;
  LL_TIM_Init(TIM4, &TIM_InitStruct);
  LL_TIM_EnableARRPreload(TIM4);
  LL_TIM_SetClockSource(TIM4, LL_TIM_CLOCKSOURCE_INTERNAL);
  LL_TIM_OC_EnablePreload(TIM4, LL_TIM_CHANNEL_CH3);
  TIM_OC_InitStruct.OCMode = LL_TIM_OCMODE_PWM1;
  TIM_OC_InitStruct.OCState = LL_TIM_OCSTATE_DISABLE;
  TIM_OC_InitStruct.OCNState = LL_TIM_OCSTATE_DISABLE;
  TIM_OC_InitStruct.CompareValue = 0;
  TIM_OC_InitStruct.OCPolarity = LL_TIM_OCPOLARITY_HIGH;
  LL_TIM_OC_Init(TIM4, LL_TIM_CHANNEL_CH3, &TIM_OC_InitStruct);
  LL_TIM_OC_DisableFast(TIM4, LL_TIM_CHANNEL_CH3);
  LL_TIM_SetTriggerInput(TIM4, LL_TIM_TS_ITR1);
  LL_TIM_SetSlaveMode(TIM4, LL_TIM_SLAVEMODE_TRIGGER);
  LL_TIM_DisableIT_TRIG(TIM4);
  LL_TIM_DisableDMAReq_TRIG(TIM4);
  LL_TIM_SetTriggerOutput(TIM4, LL_TIM_TRGO_UPDATE);
  LL_TIM_DisableMasterSlaveMode(TIM4);
  LL_AHB1_GRP1_EnableClock(LL_AHB1_GRP1_PERIPH_GPIOB);
  /**TIM4 GPIO Configuration
  PB8   ------> TIM4_CH3
  */
  GPIO_InitStruct.Pin = LL_GPIO_PIN_8;
  GPIO_InitStruct.Mode = LL_GPIO_MODE_ALTERNATE;
  GPIO_InitStruct.Speed = LL_GPIO_SPEED_FREQ_LOW;
  GPIO_InitStruct.OutputType = LL_GPIO_OUTPUT_PUSHPULL;
  GPIO_InitStruct.Pull = LL_GPIO_PULL_NO;
  GPIO_InitStruct.Alternate = LL_GPIO_AF_2;
  LL_GPIO_Init(GPIOB, &GPIO_InitStruct);

}

static void MX_TIM6_Init(void)
{

  TIM_MasterConfigTypeDef sMasterConfig = {0};

  htim6.Instance = TIM6;
  htim6.Init.Prescaler = 0;
  htim6.Init.CounterMode = TIM_COUNTERMODE_UP;
  htim6.Init.Period = 65535;
  htim6.Init.AutoReloadPreload = TIM_AUTORELOAD_PRELOAD_DISABLE;
  if (HAL_TIM_Base_Init(&htim6) != HAL_OK)
  {
    Error_Handler();
  }
  sMasterConfig.MasterOutputTrigger = TIM_TRGO_UPDATE;
  sMasterConfig.MasterSlaveMode = TIM_MASTERSLAVEMODE_DISABLE;
  if (HAL_TIMEx_MasterConfigSynchronization(&htim6, &sMasterConfig) != HAL_OK)
  {
    Error_Handler();
  }

}

static void MX_TIM8_Init(void)
{

  LL_TIM_InitTypeDef TIM_InitStruct = {0};

  LL_GPIO_InitTypeDef GPIO_InitStruct = {0};

  /* Peripheral clock enable */
  LL_APB2_GRP1_EnableClock(LL_APB2_GRP1_PERIPH_TIM8);

  LL_AHB1_GRP1_EnableClock(LL_AHB1_GRP1_PERIPH_GPIOC);
  /**TIM8 GPIO Configuration
  PC9   ------> TIM8_CH4
  */
  GPIO_InitStruct.Pin = LL_GPIO_PIN_9;
  GPIO_InitStruct.Mode = LL_GPIO_MODE_ALTERNATE;
  GPIO_InitStruct.Speed = LL_GPIO_SPEED_FREQ_LOW;
  GPIO_InitStruct.OutputType = LL_GPIO_OUTPUT_PUSHPULL;
  GPIO_InitStruct.Pull = LL_GPIO_PULL_NO;
  GPIO_InitStruct.Alternate = LL_GPIO_AF_4;
  LL_GPIO_Init(GPIOC, &GPIO_InitStruct);

  /* TIM8 DMA Init */

  /* TIM8_CH4_TRIG_COM Init */
  LL_DMA_SetDataTransferDirection(DMA2, LL_DMA_CHANNEL_2, LL_DMA_DIRECTION_PERIPH_TO_MEMORY);

  LL_DMA_SetChannelPriorityLevel(DMA2, LL_DMA_CHANNEL_2, LL_DMA_PRIORITY_HIGH);

  LL_DMA_SetMode(DMA2, LL_DMA_CHANNEL_2, LL_DMA_MODE_NORMAL);

  LL_DMA_SetPeriphIncMode(DMA2, LL_DMA_CHANNEL_2, LL_DMA_PERIPH_NOINCREMENT);

  LL_DMA_SetMemoryIncMode(DMA2, LL_DMA_CHANNEL_2, LL_DMA_MEMORY_INCREMENT);

  LL_DMA_SetPeriphSize(DMA2, LL_DMA_CHANNEL_2, LL_DMA_PDATAALIGN_HALFWORD);

  LL_DMA_SetMemorySize(DMA2, LL_DMA_CHANNEL_2, LL_DMA_MDATAALIGN_HALFWORD);

  TIM_InitStruct.Prescaler = 0;
  TIM_InitStruct.CounterMode = LL_TIM_COUNTERMODE_UP;
  TIM_InitStruct.Autoreload = 65535;
  TIM_InitStruct.ClockDivision = LL_TIM_CLOCKDIVISION_DIV1;
  TIM_InitStruct.RepetitionCounter = 0;
  LL_TIM_Init(TIM8, &TIM_InitStruct);
  LL_TIM_DisableARRPreload(TIM8);
  LL_TIM_SetTriggerOutput(TIM8, LL_TIM_TRGO_RESET);
  LL_TIM_SetTriggerOutput2(TIM8, LL_TIM_TRGO2_RESET);
  LL_TIM_DisableMasterSlaveMode(TIM8);
  LL_TIM_IC_SetActiveInput(TIM8, LL_TIM_CHANNEL_CH4, LL_TIM_ACTIVEINPUT_DIRECTTI);
  LL_TIM_IC_SetPrescaler(TIM8, LL_TIM_CHANNEL_CH4, LL_TIM_ICPSC_DIV1);
  LL_TIM_IC_SetFilter(TIM8, LL_TIM_CHANNEL_CH4, LL_TIM_IC_FILTER_FDIV1);
  LL_TIM_IC_SetPolarity(TIM8, LL_TIM_CHANNEL_CH4, LL_TIM_IC_POLARITY_RISING);

}

static void MX_USART2_UART_Init(void)
{

  LL_USART_InitTypeDef USART_InitStruct = {0};

  LL_GPIO_InitTypeDef GPIO_InitStruct = {0};

  /* Peripheral clock enable */
  LL_APB1_GRP1_EnableClock(LL_APB1_GRP1_PERIPH_USART2);

  LL_AHB1_GRP1_EnableClock(LL_AHB1_GRP1_PERIPH_GPIOA);
  /**USART2 GPIO Configuration
  PA2   ------> USART2_TX
  PA3   ------> USART2_RX
  */
  GPIO_InitStruct.Pin = USART_TX_Pin|USART_RX_Pin;
  GPIO_InitStruct.Mode = LL_GPIO_MODE_ALTERNATE;
  GPIO_InitStruct.Speed = LL_GPIO_SPEED_FREQ_LOW;
  GPIO_InitStruct.OutputType = LL_GPIO_OUTPUT_PUSHPULL;
  GPIO_InitStruct.Pull = LL_GPIO_PULL_NO;
  GPIO_InitStruct.Alternate = LL_GPIO_AF_7;
  LL_GPIO_Init(GPIOA, &GPIO_InitStruct);

  USART_InitStruct.BaudRate = 115200;
  USART_InitStruct.DataWidth = LL_USART_DATAWIDTH_8B;
  USART_InitStruct.StopBits = LL_USART_STOPBITS_1;
  USART_InitStruct.Parity = LL_USART_PARITY_NONE;
  USART_InitStruct.TransferDirection = LL_USART_DIRECTION_TX_RX;
  USART_InitStruct.HardwareFlowControl = LL_USART_HWCONTROL_NONE;
  USART_InitStruct.OverSampling = LL_USART_OVERSAMPLING_16;
  LL_USART_Init(USART2, &USART_InitStruct);
  LL_USART_DisableIT_CTS(USART2);
  LL_USART_ConfigAsyncMode(USART2);
  LL_USART_Enable(USART2);

}

static void MX_DMA_Init(void)
{

  /* Init with LL driver */
  /* DMA controller clock enable */
  LL_AHB1_GRP1_EnableClock(LL_AHB1_GRP1_PERIPH_DMA1);
  LL_AHB1_GRP1_EnableClock(LL_AHB1_GRP1_PERIPH_DMA2);

}

static void MX_GPIO_Init(void)
{
  LL_EXTI_InitTypeDef EXTI_InitStruct = {0};
  LL_GPIO_InitTypeDef GPIO_InitStruct = {0};

  /* GPIO Ports Clock Enable */
  LL_AHB1_GRP1_EnableClock(LL_AHB1_GRP1_PERIPH_GPIOC);
  LL_AHB1_GRP1_EnableClock(LL_AHB1_GRP1_PERIPH_GPIOF);
  LL_AHB1_GRP1_EnableClock(LL_AHB1_GRP1_PERIPH_GPIOA);
  LL_AHB1_GRP1_EnableClock(LL_AHB1_GRP1_PERIPH_GPIOB);

  /**/
  LL_GPIO_ResetOutputPin(LD2_GPIO_Port, LD2_Pin);

  /**/
  LL_SYSCFG_SetEXTISource(LL_SYSCFG_EXTI_PORTC, LL_SYSCFG_EXTI_LINE13);

  /**/
  LL_GPIO_SetPinPull(B1_GPIO_Port, B1_Pin, LL_GPIO_PULL_NO);

  /**/
  LL_GPIO_SetPinMode(B1_GPIO_Port, B1_Pin, LL_GPIO_MODE_INPUT);

  /**/
  EXTI_InitStruct.Line_0_31 = LL_EXTI_LINE_13;
  EXTI_InitStruct.Line_32_63 = LL_EXTI_LINE_NONE;
  EXTI_InitStruct.LineCommand = ENABLE;
  EXTI_InitStruct.Mode = LL_EXTI_MODE_IT;
  EXTI_InitStruct.Trigger = LL_EXTI_TRIGGER_FALLING;
  LL_EXTI_Init(&EXTI_InitStruct);

  /**/
  GPIO_InitStruct.Pin = LD2_Pin;
  GPIO_InitStruct.Mode = LL_GPIO_MODE_OUTPUT;
  GPIO_InitStruct.Speed = LL_GPIO_SPEED_FREQ_LOW;
  GPIO_InitStruct.OutputType = LL_GPIO_OUTPUT_PUSHPULL;
  GPIO_InitStruct.Pull = LL_GPIO_PULL_NO;
  LL_GPIO_Init(LD2_GPIO_Port, &GPIO_InitStruct);

}

void Error_Handler(void)
{
}

/************************ (C) COPYRIGHT STMicroelectronics *****END OF FILE****/
